# APM32F465 register map
File version: 1.0
CPU: CM4 r1p0, little endian, no MPU, no FPU, 3 interrupt priority bits
Registers are 32-bit, read-write, reset 0x0 unless marked. A register's access mark holds for its fields unless they carry their own. Offsets are from the block's base; [hi:lo] are bit positions; {n}, {i} and the like mark numbered series; 'fields as' and 'values as' point back to an identical list.

## OTG_HS1_GLOBAL — USB on the go high speed
Base 0x40040000
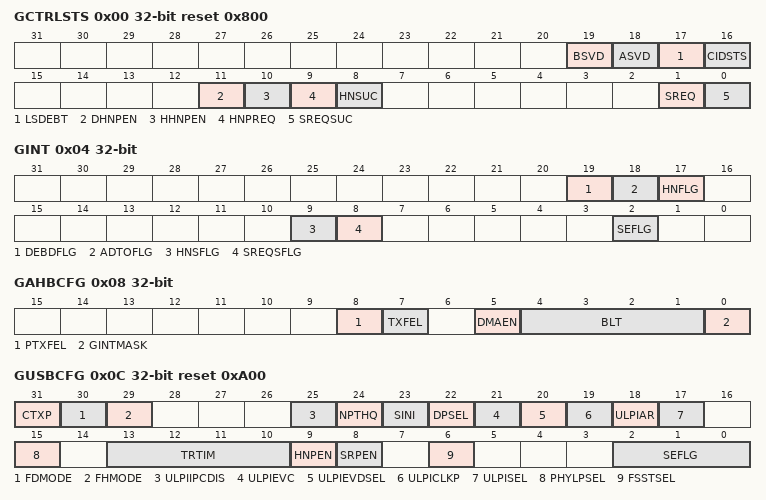
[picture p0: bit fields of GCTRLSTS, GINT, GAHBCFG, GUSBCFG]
0x00 GCTRLSTS access per field reset 0x800 — OTG_HS control and status register
  [19] BSVD ro — B-session valid
  [18] ASVD ro — A-session valid
  [17] LSDEBT ro — Long/short debounce time
  [16] CIDSTS ro — Connector ID status
  [11] DHNPEN rw — Device HNP enabled
  [10] HHNPEN rw — Host set HNP enable
  [9] HNPREQ rw — HNP request
  [8] HNSUC ro — Host negotiation success
  [1] SREQ rw — Session request
  [0] SREQSUC ro — Session request success
0x04 GINT — OTG_HS interrupt register
  [19] DEBDFLG — Debounce done
  [18] ADTOFLG — A-device timeout change
  [17] HNFLG — Host negotiation detected
  [9] HNSFLG — Host negotiation success status change
  [8] SREQSFLG — Session request success status change
  [2] SEFLG — Session end detected
0x08 GAHBCFG — OTG_HS AHB configuration register
  [8] PTXFEL — Periodic TxFIFO empty level
  [7] TXFEL — TxFIFO empty level
  [5] DMAEN — DMA enable
  [4:1] BLT — Burst length/type
  [0] GINTMASK — Global interrupt mask
0x0C GUSBCFG access per field reset 0xA00 — OTG_HS USB configuration register
  [31] CTXP rw — Corrupt Tx packet
  [30] FDMODE rw — Forced peripheral mode
  [29] FHMODE rw — Forced host mode
  [25] ULPIIPCDIS rw — ULPI interface protect disable
  [24] NPTHQ rw — No Pass Through Qualified
  [23] SINI rw — Signal Invert
  [22] DPSEL rw — TermSel DLine pulsing selection
  [21] ULPIEVC rw — ULPI external VBUS indicator
  [20] ULPIEVDSEL rw — ULPI External VBUS Drive
  [19] ULPICLKP rw — ULPI Clock SuspendM
  [18] ULPIAR rw — ULPI Auto-resume
  [17] ULPISEL rw — ULPI FS/LS select
  [15] PHYLPSEL rw — PHY Low-power clock select
  [13:10] TRTIM rw — USB turnaround time
  [9] HNPEN rw — HNP-capable
  [8] SRPEN rw — SRP-capable
  [6] FSSTSEL wo — USB 2.0 high-speed ULPI PHY or USB 1.1 full-speed serial transceiver select
  [2:0] SEFLG rw — FS timeout calibration
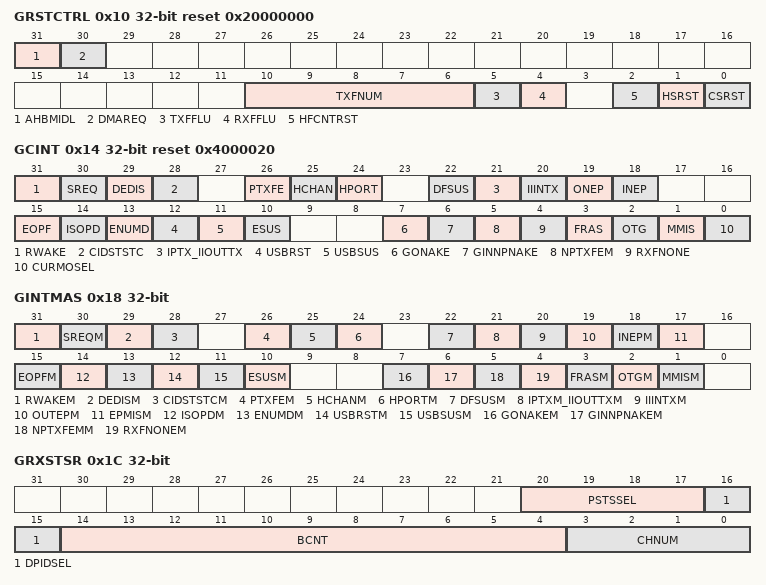
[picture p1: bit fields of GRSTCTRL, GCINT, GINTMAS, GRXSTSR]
0x10 GRSTCTRL access per field reset 0x20000000 — OTG_HS reset register
  [31] AHBMIDL ro — AHB master idle
  [30] DMAREQ ro — DMA request signal
  [10:6] TXFNUM rw — TxFIFO number
  [5] TXFFLU rw — TxFIFO flush
  [4] RXFFLU rw — RxFIFO flush
  [2] HFCNTRST rw — Host frame counter reset
  [1] HSRST rw — HCLK soft reset
  [0] CSRST rw — Core soft reset
0x14 GCINT access per field reset 0x4000020 — OTG_HS core interrupt register
  [31] RWAKE rw — Resume/remote wakeup detected interrupt
  [30] SREQ rw — Session request/new session detected interrupt
  [29] DEDIS rw — Disconnect detected interrupt
  [28] CIDSTSTC rw — Connector ID status change
  [26] PTXFE ro — Periodic TxFIFO empty
  [25] HCHAN ro — Host channels interrupt
  [24] HPORT ro — Host port interrupt
  [22] DFSUS rw — Data fetch suspended
  [21] IPTX_IIOUTTX rw — Incomplete periodic transfer
  [20] IIINTX rw — Incomplete isochronous IN transfer
  [19] ONEP ro — OUT endpoint interrupt
  [18] INEP ro — IN endpoint interrupt
  [15] EOPF rw — End of periodic frame interrupt
  [14] ISOPD rw — Isochronous OUT packet dropped interrupt
  [13] ENUMD rw — Enumeration done
  [12] USBRST rw — USB reset
  [11] USBSUS rw — USB suspend
  [10] ESUS rw — Early suspend
  [7] GONAKE ro — Global OUT NAK effective
  [6] GINNPNAKE ro — Global IN nonperiodic NAK effective
  [5] NPTXFEM ro — Nonperiodic TxFIFO empty
  [4] RXFNONE ro — RxFIFO nonempty
  [3] FRAS rw — Start of frame
  [2] OTG ro — OTG interrupt
  [1] MMIS rw — Mode mismatch interrupt
  [0] CURMOSEL ro — Current mode of operation
0x18 GINTMAS access per field — OTG_HS interrupt mask register
  [31] RWAKEM rw — Resume/remote wakeup detected interrupt mask
  [30] SREQM rw — Session request/new session detected interrupt mask
  [29] DEDISM rw — Disconnect detected interrupt mask
  [28] CIDSTSTCM rw — Connector ID status change mask
  [26] PTXFEM rw — Periodic TxFIFO empty mask
  [25] HCHANM rw — Host channels interrupt mask
  [24] HPORTM ro — Host port interrupt mask
  [22] DFSUSM rw — Data fetch suspended mask
  [21] IPTXM_IIOUTTXM rw — Incomplete periodic transfer mask
  [20] IIINTXM rw — Incomplete isochronous IN transfer mask
  [19] OUTEPM rw — OUT endpoints interrupt mask
  [18] INEPM rw — IN endpoints interrupt mask
  [17] EPMISM rw — Endpoint mismatch interrupt mask
  [15] EOPFM rw — End of periodic frame interrupt mask
  [14] ISOPDM rw — Isochronous OUT packet dropped interrupt mask
  [13] ENUMDM rw — Enumeration done mask
  [12] USBRSTM rw — USB reset mask
  [11] USBSUSM rw — USB suspend mask
  [10] ESUSM rw — Early suspend mask
  [7] GONAKEM rw — Global OUT NAK effective mask
  [6] GINNPNAKEM rw — Global nonperiodic IN NAK effective mask
  [5] NPTXFEMM rw — Nonperiodic TxFIFO empty mask
  [4] RXFNONEM rw — Receive FIFO nonempty mask
  [3] FRASM rw — Start of frame mask
  [2] OTGM rw — OTG interrupt mask
  [1] MMISM rw — Mode mismatch interrupt mask
0x1C GRXSTSR ro — OTG_HS Receive status debug read register (host mode)
  [20:17] PSTSSEL — Packet status
  [16:15] DPIDSEL — Data PID
  [14:4] BCNT — Byte count
  [3:0] CHNUM — Channel number
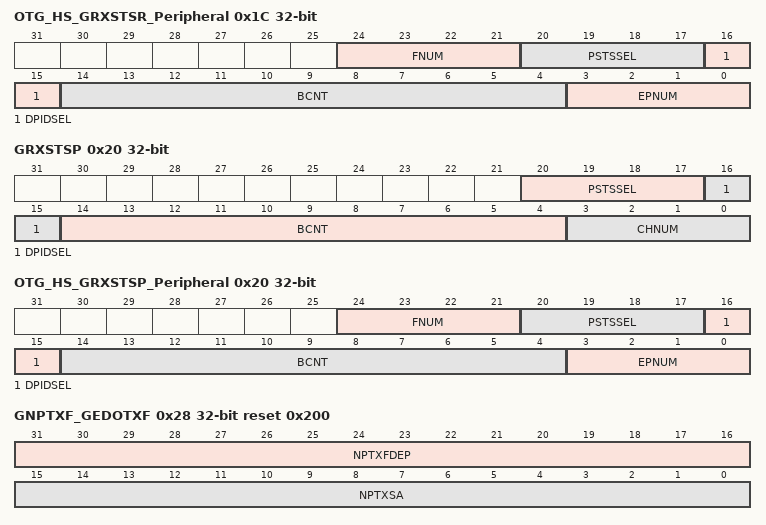
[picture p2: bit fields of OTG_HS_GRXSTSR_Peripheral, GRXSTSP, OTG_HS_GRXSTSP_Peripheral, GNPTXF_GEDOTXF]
0x1C OTG_HS_GRXSTSR_Peripheral ro (alternate view of GRXSTSR) — OTG_HS Receive status debug read register (peripheral mode mode)
  [24:21] FNUM — Frame number
  [20:17] PSTSSEL — Packet status
  [16:15] DPIDSEL — Data PID
  [14:4] BCNT — Byte count
  [3:0] EPNUM — Endpoint number
0x20 GRXSTSP ro — OTG_HS status read and pop register (host mode)
  fields as GRXSTSR
0x20 OTG_HS_GRXSTSP_Peripheral ro (alternate view of GRXSTSP) — OTG_HS status read and pop register (peripheral mode)
  fields as OTG_HS_GRXSTSR_Peripheral
0x24 GRXFIFO reset 0x200 — OTG_HS Receive FIFO size register
  [15:0] RXFDEP — RxFIFO depth
0x28 GNPTXF_GEDOTXF reset 0x200 — OTG_HS nonperiodic transmit FIFO size register (host mode)
  [31:16] NPTXFDEP — Nonperiodic TxFIFO depth
  [15:0] NPTXSA — Nonperiodic transmit RAM start address
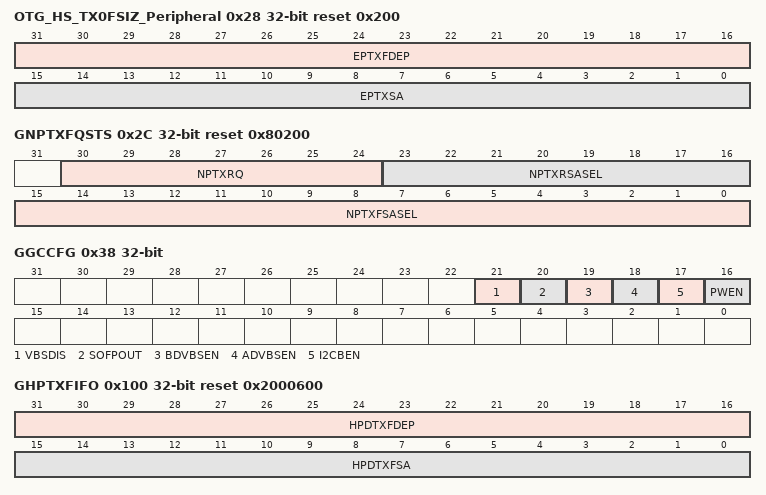
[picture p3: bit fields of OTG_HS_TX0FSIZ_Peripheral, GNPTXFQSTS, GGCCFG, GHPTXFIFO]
0x28 OTG_HS_TX0FSIZ_Peripheral reset 0x200 (alternate view of GNPTXF_GEDOTXF) — Endpoint 0 transmit FIFO size (peripheral mode)
  [31:16] EPTXFDEP — Endpoint 0 TxFIFO depth
  [15:0] EPTXSA — Endpoint 0 transmit RAM start address
0x2C GNPTXFQSTS ro reset 0x80200 — OTG_HS nonperiodic transmit FIFO/queue status register
  [30:24] NPTXRQ — Top of the nonperiodic transmit request queue
  [23:16] NPTXRSASEL — Nonperiodic transmit request queue space available
  [15:0] NPTXFSASEL — Nonperiodic TxFIFO space available
0x38 GGCCFG — OTG_HS general core configuration register
  [21] VBSDIS — VBUS sensing disable option
  [20] SOFPOUT — SOF output enable
  [19] BDVBSEN — Enable the VBUS sensing device
  [18] ADVBSEN — Enable the VBUS sensing device
  [17] I2CBEN — Enable I2C bus connection for the external I2C PHY interface
  [16] PWEN — Power down
0x3C GCID reset 0x1200 — OTG_HS core ID register
  [31:0] PID — Product ID field
0x100 GHPTXFIFO reset 0x2000600 — OTG_HS Host periodic transmit FIFO size register
  [31:16] HPDTXFDEP — Host periodic TxFIFO depth
  [15:0] HPDTXFSA — Host periodic TxFIFO start address
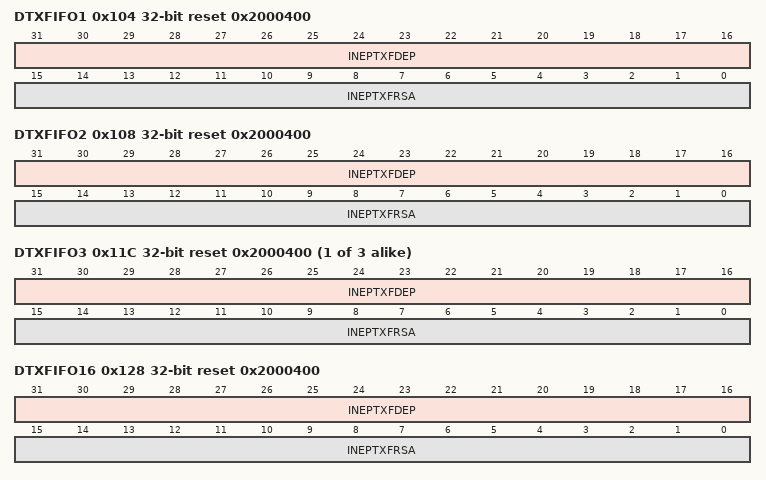
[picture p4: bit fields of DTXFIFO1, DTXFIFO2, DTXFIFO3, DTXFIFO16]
0x104 DTXFIFO1 reset 0x2000400 — OTG_HS device IN endpoint transmit FIFO size register
  [31:16] INEPTXFDEP — IN endpoint TxFIFO depth
  [15:0] INEPTXFRSA — IN endpoint FIFOx transmit RAM start address
0x108 DTXFIFO2 reset 0x2000400 — OTG_HS device IN endpoint transmit FIFO size register
  fields as DTXFIFO1
{0x110+4i} DTXFIFO{i} reset 0x2000400 (i=3..5) — OTG_HS device IN endpoint transmit FIFO size register
  fields as DTXFIFO1
0x128 DTXFIFO16 reset 0x2000400 — OTG_HS device IN endpoint transmit FIFO size register
  fields as DTXFIFO1
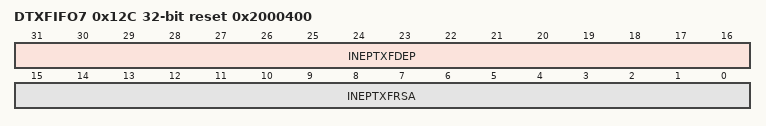
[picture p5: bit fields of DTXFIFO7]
0x12C DTXFIFO7 reset 0x2000400 — OTG_HS device IN endpoint transmit FIFO size register
  fields as DTXFIFO1
